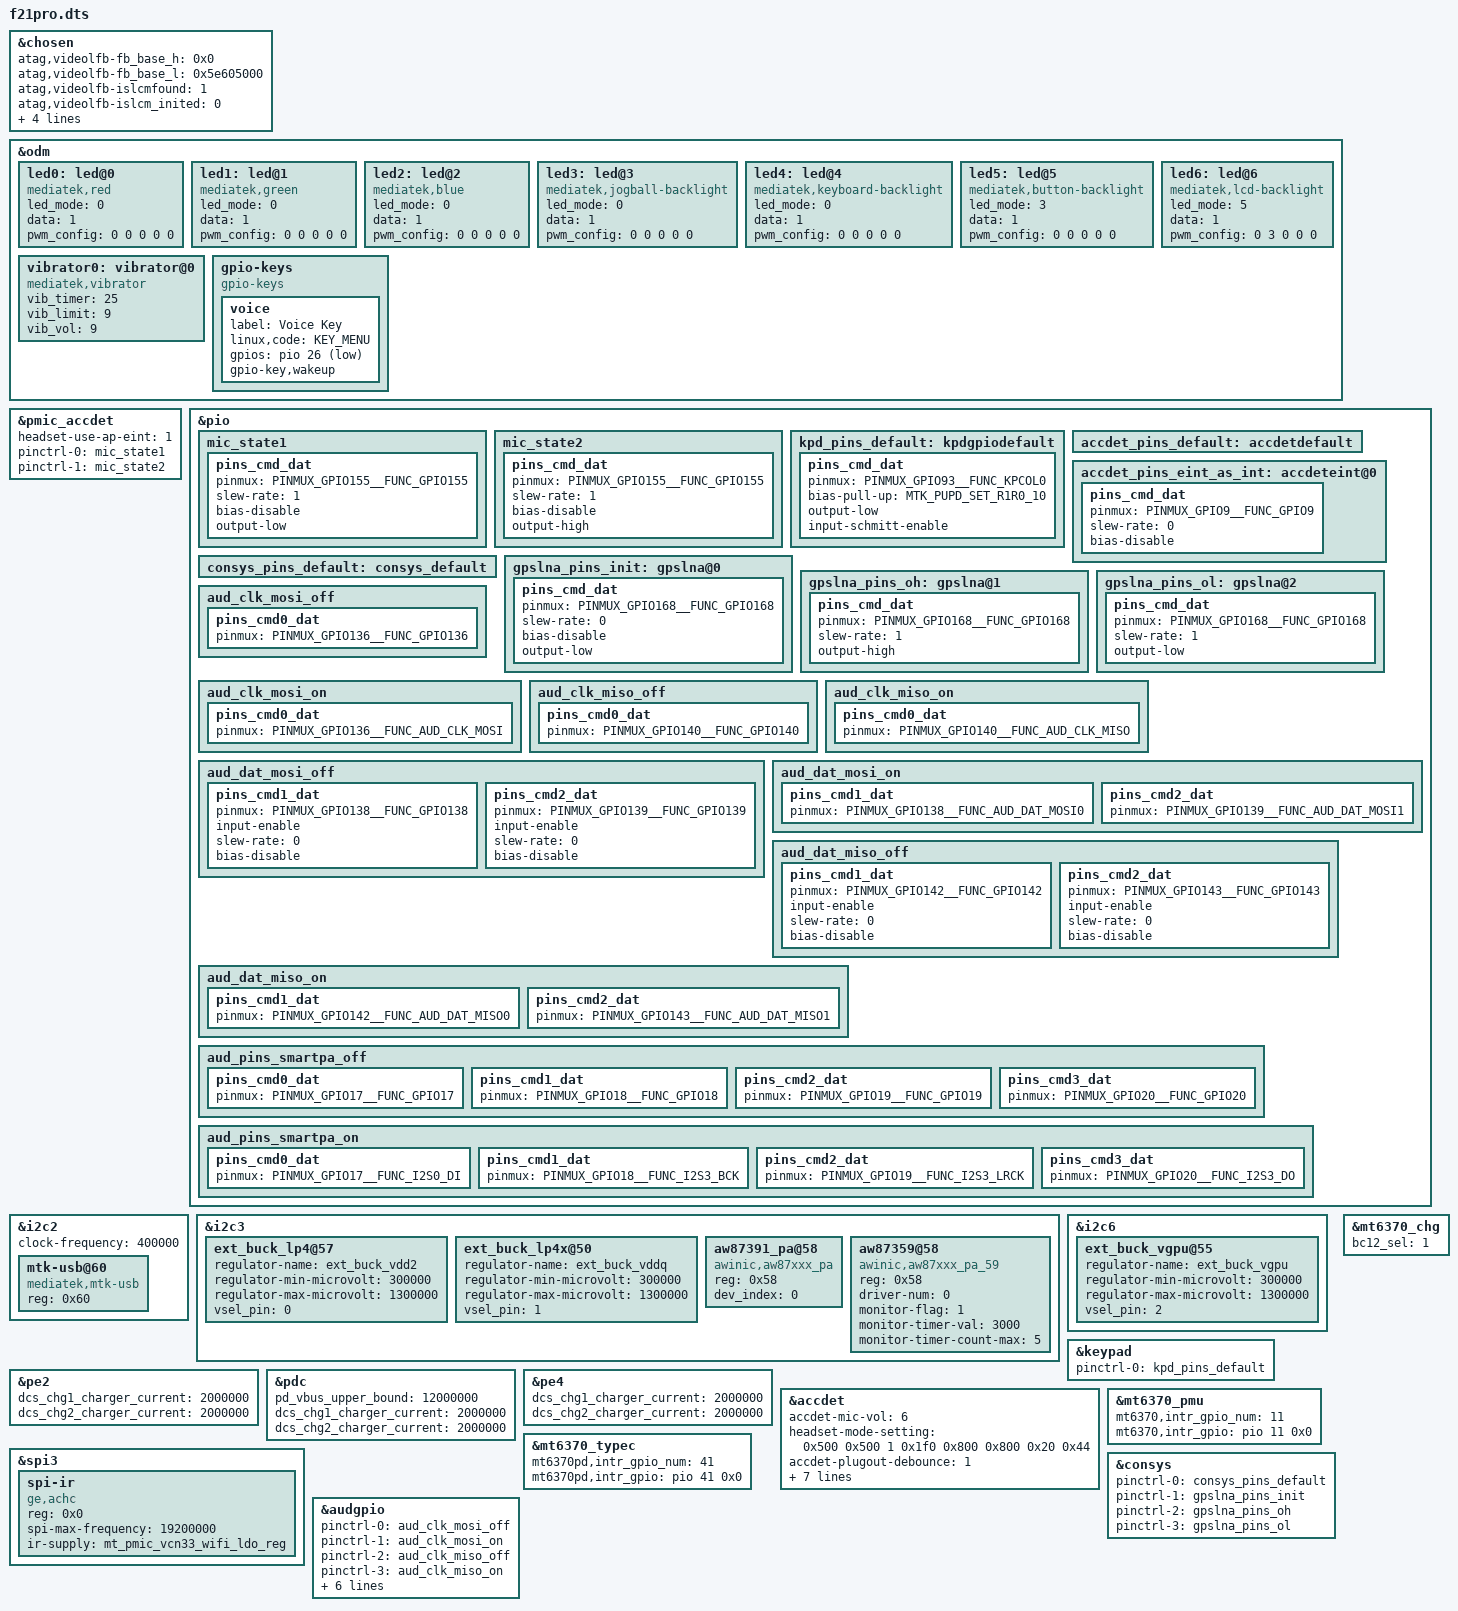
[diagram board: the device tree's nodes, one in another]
// SPDX-License-Identifier: GPL-2.0+
/*
 * Mon Mar 25 18:47:30 CST 2024 stock v4.19.127 dtbo.img overrides to make identical f21pro.dtbo
 * Based on k61v1_64_bsp.dts
 *
 * Copyright (c) 2019 MediaTek Inc.
 * Copyright (c) 2025 Jami Kettunen <jami.kettunen@protonmail.com>
 */

#include <dt-bindings/interrupt-controller/arm-gic.h>
#include <dt-bindings/interrupt-controller/irq.h>
#include <dt-bindings/pinctrl/mt6761-pinfunc.h>
#include <dt-bindings/mmc/mt6761-msdc.h>
#include <dt-bindings/clock/mt6761-clk.h>
#include <dt-bindings/input/input.h>
#include <dt-bindings/gpio/gpio.h>

/dts-v1/;
/plugin/;

/* chosen */
&chosen {

	/* fpga may has no lk, we need to specify display info here */
	/* fb buffer is reserved using this dts by memory node above */
	atag,videolfb-fb_base_h = <0x0>;
	atag,videolfb-fb_base_l = <0x5e605000>;
	atag,videolfb-islcmfound = <1>;
	/* because no lk, so lcm is not inited */
	atag,videolfb-islcm_inited = <0>;
	atag,videolfb-fps= <6000>;
	atag,videolfb-vramSize= <0x017bb000>;
	atag,videolfb-lcmname= "nt35521_hd_dsi_vdo_truly_rt5081_drv";
};

&odm {
	led0:led@0 {
		compatible = "mediatek,red";
		led_mode = <0>;
		data = <1>;
		pwm_config = <0 0 0 0 0>;
	};
	led1:led@1 {
		compatible = "mediatek,green";
		led_mode = <0>;
		data = <1>;
		pwm_config = <0 0 0 0 0>;
	};
	led2:led@2 {
		compatible = "mediatek,blue";
		led_mode = <0>;
		data = <1>;
		pwm_config = <0 0 0 0 0>;
	};
	led3:led@3 {
		compatible = "mediatek,jogball-backlight";
		led_mode = <0>;
		data = <1>;
		pwm_config = <0 0 0 0 0>;
	};
	led4:led@4 {
		compatible = "mediatek,keyboard-backlight";
		led_mode = <0>;
		data = <1>;
		pwm_config = <0 0 0 0 0>;
	};
	led5:led@5 {
		compatible = "mediatek,button-backlight";
		led_mode = <3>;
		data = <1>;
		pwm_config = <0 0 0 0 0>;
	};
	led6:led@6 {
		compatible = "mediatek,lcd-backlight";
		led_mode = <5>;
		data = <1>;
		pwm_config = <0 3 0 0 0>;
	};
	vibrator0:vibrator@0 {
		compatible = "mediatek,vibrator";
		vib_timer = <25>;
		vib_limit = <9>;
		vib_vol= <9>;
	};

	/* top-left keypad button */
	gpio-keys {
		compatible = "gpio-keys";

		voice {
			label = "Voice Key";
			linux,code = <KEY_MENU>;
			gpios = <&pio 26 GPIO_ACTIVE_LOW>;
			gpio-key,wakeup;
		};
	};
};

&pmic_accdet {
	headset-use-ap-eint = <1>;

	pinctrl-names = "mic_state1", "mic_state2";
	pinctrl-0 = <&mic_state1>;
	pinctrl-1 = <&mic_state2>;
};

&pio {
	mic_state1: mic_state1 {
		pins_cmd_dat {
			pinmux = <PINMUX_GPIO155__FUNC_GPIO155>;
			slew-rate = <1>;
			bias-disable;
			output-low;
		};
	};

	mic_state2: mic_state2 {
		pins_cmd_dat {
			pinmux = <PINMUX_GPIO155__FUNC_GPIO155>;
			slew-rate = <1>;
			bias-disable;
			output-high;
		};
	};
};

&i2c2 {
	#address-cells = <1>;
	#size-cells = <0>;
	clock-frequency = <400000>;

	mtk-usb@60 {
		compatible = "mediatek,mtk-usb";
		reg = <0x60>;
		status = "okay";
	};
};

&i2c3 {
	ext_buck_lp4@57 {
		regulator-name ="ext_buck_vdd2";
		regulator-min-microvolt = <300000>;
		regulator-max-microvolt = <1300000>;
		vsel_pin = <0>;
	};

	ext_buck_lp4x@50 {
		regulator-name ="ext_buck_vddq";
		regulator-min-microvolt = <300000>;
		regulator-max-microvolt = <1300000>;
		vsel_pin = <1>;
	};
};

&i2c6 {
	ext_buck_vgpu@55 {
		regulator-name ="ext_buck_vgpu";
		regulator-min-microvolt = <300000>;
		regulator-max-microvolt = <1300000>;
		vsel_pin = <2>;
	};
};

&keypad {
	pinctrl-names = "default";
	pinctrl-0 = <&kpd_pins_default>;
};

&pio {
	kpd_pins_default: kpdgpiodefault {
		pins_cmd_dat {
			pinmux = <PINMUX_GPIO93__FUNC_KPCOL0>;
			bias-pull-up = <MTK_PUPD_SET_R1R0_10>;
			output-low;
			input-schmitt-enable;
		};
	};
};

&pe2 {
	dcs_chg1_charger_current = <2000000>;
	dcs_chg2_charger_current = <2000000>;
};

&pdc {
	pd_vbus_upper_bound = <12000000>;
	dcs_chg1_charger_current = <2000000>;
	dcs_chg2_charger_current = <2000000>;
};

&pe4 {
	dcs_chg1_charger_current = <2000000>;
	dcs_chg2_charger_current = <2000000>;
};

&accdet {
	accdet-mic-vol = <6>;
	headset-mode-setting = <0x500 0x500 1 0x1f0 0x800 0x800 0x20 0x44>;
	accdet-plugout-debounce = <1>;
	accdet-mic-mode = <1>;
	headset-eint-level-pol = <8>;
	headset-three-key-threshold = <0 80 220 400>;
	headset-three-key-threshold-CDD = <0 121 192 600>;
	headset-four-key-threshold = <0 58 121 192 400>;
	pinctrl-names = "default", "state_eint_as_int";
	pinctrl-0 = <&accdet_pins_default>;
	pinctrl-1 = <&accdet_pins_eint_as_int>;
	status = "okay";
};
&pio {
	accdet_pins_default: accdetdefault {
	};
	accdet_pins_eint_as_int: accdeteint@0 {
		pins_cmd_dat {
			pinmux = <PINMUX_GPIO9__FUNC_GPIO9>;
			slew-rate = <0>;
			bias-disable;
		};
	};
};

&mt6370_pmu {
	mt6370,intr_gpio_num = <11>; /* direct defined GPIO num */
	mt6370,intr_gpio = <&pio 11 0x0>;
};

&i2c3 {
	status = "okay";

	aw87391_pa@58 {
		compatible = "awinic,aw87xxx_pa";
		reg = <0x58>;
		dev_index = <0>;
		status = "okay";
	};

	aw87359@58 {
		status = "okay";
		compatible = "awinic,aw87xxx_pa_59";
		reg = <0x58>;
		driver-num = <0>;
		monitor-flag = <1>;
		monitor-timer-val = <3000>;
		monitor-timer-count-max = <5>;
	};
};

&spi3 {
	status = "okay";

	spi-ir {
		compatible = "ge,achc";
		reg = <0x0>;
		spi-max-frequency = <19200000>;
		ir-supply = <&mt_pmic_vcn33_wifi_ldo_reg>;
	};
};

&mt6370_typec {
	mt6370pd,intr_gpio_num = <41>; /* direct defined GPIO num */
	mt6370pd,intr_gpio = <&pio 41 0x0>;
};
/* CONSYS GPIO standardization */
&pio {
	consys_pins_default: consys_default {
	};
	gpslna_pins_init: gpslna@0 {
		pins_cmd_dat {
			pinmux = <PINMUX_GPIO168__FUNC_GPIO168>;
			slew-rate = <0>;
			bias-disable;
			output-low;
		};
	};
	gpslna_pins_oh: gpslna@1 {
		pins_cmd_dat {
			pinmux = <PINMUX_GPIO168__FUNC_GPIO168>;
			slew-rate = <1>;
			output-high;
		};
	};
	gpslna_pins_ol: gpslna@2 {
		pins_cmd_dat {
			pinmux = <PINMUX_GPIO168__FUNC_GPIO168>;
			slew-rate = <1>;
			output-low;
		};
	};
};
&consys {
	pinctrl-names = "default", "gps_lna_state_init",
		"gps_lna_state_oh", "gps_lna_state_ol";
	pinctrl-0 = <&consys_pins_default>;
	pinctrl-1 = <&gpslna_pins_init>;
	pinctrl-2 = <&gpslna_pins_oh>;
	pinctrl-3 = <&gpslna_pins_ol>;
	status = "okay";
};
/* CONSYS end */

/* AUDIO GPIO standardization */
&audgpio {
	pinctrl-names = "aud_clk_mosi_off",
			"aud_clk_mosi_on",
			"aud_clk_miso_off",
			"aud_clk_miso_on",
			"aud_dat_mosi_off",
			"aud_dat_mosi_on",
			"aud_dat_miso_off",
			"aud_dat_miso_on",
			"aud_smartpa_off",
			"aud_smartpa_on";
	pinctrl-0 = <&aud_clk_mosi_off>;
	pinctrl-1 = <&aud_clk_mosi_on>;
	pinctrl-2 = <&aud_clk_miso_off>;
	pinctrl-3 = <&aud_clk_miso_on>;
	pinctrl-4 = <&aud_dat_mosi_off>;
	pinctrl-5 = <&aud_dat_mosi_on>;
	pinctrl-6 = <&aud_dat_miso_off>;
	pinctrl-7 = <&aud_dat_miso_on>;
	pinctrl-8 = <&aud_pins_smartpa_off>;
	pinctrl-9 = <&aud_pins_smartpa_on>;
	status = "okay";
};

&pio {
	aud_clk_mosi_off: aud_clk_mosi_off {
		pins_cmd0_dat {
			pinmux = <PINMUX_GPIO136__FUNC_GPIO136>;
		};
	};

	aud_clk_mosi_on: aud_clk_mosi_on {
		pins_cmd0_dat {
			pinmux = <PINMUX_GPIO136__FUNC_AUD_CLK_MOSI>;
		};
	};

	aud_clk_miso_off: aud_clk_miso_off {
		pins_cmd0_dat {
			pinmux = <PINMUX_GPIO140__FUNC_GPIO140>;
		};
	};

	aud_clk_miso_on: aud_clk_miso_on {
		pins_cmd0_dat {
			pinmux = <PINMUX_GPIO140__FUNC_AUD_CLK_MISO>;
		};
	};

	aud_dat_mosi_off: aud_dat_mosi_off {
		pins_cmd1_dat {
			pinmux = <PINMUX_GPIO138__FUNC_GPIO138>;
			input-enable;
			slew-rate = <0>;
			bias-disable;
		};
		pins_cmd2_dat {
			pinmux = <PINMUX_GPIO139__FUNC_GPIO139>;
			input-enable;
			slew-rate = <0>;
			bias-disable;
		};
	};

	aud_dat_mosi_on: aud_dat_mosi_on {
		pins_cmd1_dat {
			pinmux = <PINMUX_GPIO138__FUNC_AUD_DAT_MOSI0>;
		};
		pins_cmd2_dat {
			pinmux = <PINMUX_GPIO139__FUNC_AUD_DAT_MOSI1>;
		};
	};

	aud_dat_miso_off: aud_dat_miso_off {
		pins_cmd1_dat {
			pinmux = <PINMUX_GPIO142__FUNC_GPIO142>;
			input-enable;
			slew-rate = <0>;
			bias-disable;
		};
		pins_cmd2_dat {
			pinmux = <PINMUX_GPIO143__FUNC_GPIO143>;
			input-enable;
			slew-rate = <0>;
			bias-disable;
		};
	};

	aud_dat_miso_on: aud_dat_miso_on {
		pins_cmd1_dat {
			pinmux = <PINMUX_GPIO142__FUNC_AUD_DAT_MISO0>;
		};
		pins_cmd2_dat {
			pinmux = <PINMUX_GPIO143__FUNC_AUD_DAT_MISO1>;
		};
	};

	aud_pins_smartpa_off: aud_pins_smartpa_off {
		pins_cmd0_dat {
			pinmux = <PINMUX_GPIO17__FUNC_GPIO17>;
		};
		pins_cmd1_dat {
			pinmux = <PINMUX_GPIO18__FUNC_GPIO18>;
		};
		pins_cmd2_dat {
			pinmux = <PINMUX_GPIO19__FUNC_GPIO19>;
		};
		pins_cmd3_dat {
			pinmux = <PINMUX_GPIO20__FUNC_GPIO20>;
		};
	};

	aud_pins_smartpa_on: aud_pins_smartpa_on {
		pins_cmd0_dat {
			pinmux = <PINMUX_GPIO17__FUNC_I2S0_DI>;
		};
		pins_cmd1_dat {
			pinmux = <PINMUX_GPIO18__FUNC_I2S3_BCK>;
		};
		pins_cmd2_dat {
			pinmux = <PINMUX_GPIO19__FUNC_I2S3_LRCK>;
		};
		pins_cmd3_dat {
			pinmux = <PINMUX_GPIO20__FUNC_I2S3_DO>;
		};
	};
};
/* AUDIO end */

&mt6370_chg {
	bc12_sel = <1>;
};

#include "f21pro/cust.dtsi"
#include "f21pro/cust_mt6761_camera.dtsi"
#include "f21pro/cust_mt6761_touch_480x640.dtsi"
/*End of this file, DO NOT ADD ANYTHING HERE*/
